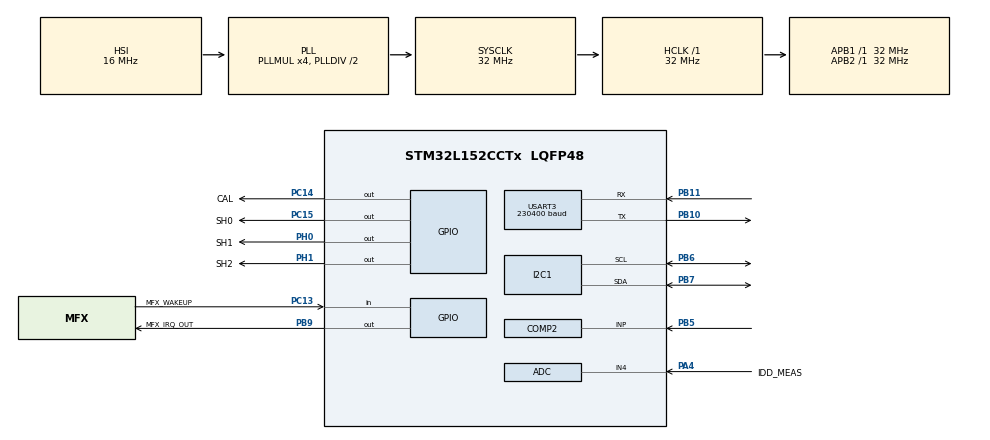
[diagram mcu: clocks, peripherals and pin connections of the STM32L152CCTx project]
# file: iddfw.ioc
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ADC.Channel-0\#ChannelRegularConversion=ADC_CHANNEL_4
ADC.ClockPrescaler=ADC_CLOCK_ASYNC_DIV4
ADC.ContinuousConvMode=DISABLE
ADC.DMAContinuousRequests=DISABLE
ADC.DataAlign=ADC_DATAALIGN_RIGHT
ADC.DiscontinuousConvMode=DISABLE
ADC.EOCSelection=ADC_EOC_SINGLE_CONV
ADC.EnableAnalogWatchDog=false
ADC.ExternalTrigConv=ADC_SOFTWARE_START
ADC.ExternalTrigConvEdge=ADC_EXTERNALTRIGCONVEDGE_NONE
ADC.InjNumberOfConversion=1
ADC.InjectedChannel-4\#ChannelInjectedConversion=ADC_CHANNEL_VREFINT
ADC.InjectedConvMode=AutoInjected
ADC.InjectedOffset-4\#ChannelInjectedConversion=0
ADC.InjectedRank-4\#ChannelInjectedConversion=1
ADC.InjectedSamplingTime-4\#ChannelInjectedConversion=ADC_SAMPLETIME_384CYCLES
ADC.LowPowerAutoPowerOff=ADC_AUTOPOWEROFF_DISABLE
ADC.LowPowerAutoWait=ADC_AUTOWAIT_DISABLE
ADC.NbrOfConversion=1
ADC.NbrOfConversionFlag=1
ADC.Rank-0\#ChannelRegularConversion=1
ADC.Resolution=ADC_RESOLUTION_12B
ADC.SamplingTime-0\#ChannelRegularConversion=ADC_SAMPLETIME_384CYCLES
ADC.ScanConvMode=ADC_SCAN_ENABLE
COMP2.InvertingInput=COMP_INVERTINGINPUT_VREFINT
COMP2.Mode=COMP_MODE_HIGHSPEED
COMP2.TriggerMode=COMP_TRIGGERMODE_IT_RISING_FALLING
Dma.ADC.2.Direction=DMA_PERIPH_TO_MEMORY
Dma.ADC.2.Instance=DMA1_Channel1
Dma.ADC.2.MemDataAlignment=DMA_MDATAALIGN_HALFWORD
Dma.ADC.2.MemInc=DMA_MINC_ENABLE
Dma.ADC.2.Mode=DMA_NORMAL
Dma.ADC.2.PeriphDataAlignment=DMA_PDATAALIGN_HALFWORD
Dma.ADC.2.PeriphInc=DMA_PINC_DISABLE
Dma.ADC.2.Priority=DMA_PRIORITY_LOW
Dma.Request0=USART3_RX
Dma.Request1=USART3_TX
Dma.Request2=ADC
Dma.USART3_RX.0.Direction=DMA_PERIPH_TO_MEMORY
Dma.USART3_RX.0.Instance=DMA1_Channel3
Dma.USART3_RX.0.MemDataAlignment=DMA_MDATAALIGN_BYTE
Dma.USART3_RX.0.MemInc=DMA_MINC_ENABLE
Dma.USART3_RX.0.Mode=DMA_NORMAL
Dma.USART3_RX.0.PeriphDataAlignment=DMA_PDATAALIGN_BYTE
Dma.USART3_RX.0.PeriphInc=DMA_PINC_DISABLE
Dma.USART3_RX.0.Priority=DMA_PRIORITY_LOW
Dma.USART3_TX.1.Direction=DMA_MEMORY_TO_PERIPH
Dma.USART3_TX.1.Instance=DMA1_Channel2
Dma.USART3_TX.1.MemDataAlignment=DMA_MDATAALIGN_BYTE
Dma.USART3_TX.1.MemInc=DMA_MINC_ENABLE
Dma.USART3_TX.1.Mode=DMA_NORMAL
Dma.USART3_TX.1.PeriphDataAlignment=DMA_PDATAALIGN_BYTE
Dma.USART3_TX.1.PeriphInc=DMA_PINC_DISABLE
Dma.USART3_TX.1.Priority=DMA_PRIORITY_LOW
IWDG.Prescaler=IWDG_PRESCALER_128
Mcu.Family=STM32L1
Mcu.Name=STM32L152CCTx
Mcu.Package=LQFP48
NVIC.ADC1_IRQn=true\:0\:0\:false\:false\:true\:true
NVIC.COMP_ACQ_IRQn=true\:0\:0\:false\:false\:true\:true
NVIC.COMP_IRQn=true\:0\:0\:false\:false\:true\:true
NVIC.DMA1_Channel1_IRQn=true\:0\:0\:false\:false\:true\:false
NVIC.DMA1_Channel2_IRQn=true\:0\:0\:false\:false\:true\:true
NVIC.DMA1_Channel3_IRQn=true\:0\:0\:false\:false\:true\:true
NVIC.I2C1_ER_IRQn=true\:0\:0\:false\:false\:true\:true
NVIC.I2C1_EV_IRQn=true\:0\:0\:false\:false\:true\:true
NVIC.PriorityGroup=NVIC_PRIORITYGROUP_4
NVIC.TIM2_IRQn=true\:0\:0\:false\:false\:true\:true
NVIC.TIM5_IRQn=true\:0\:0\:false\:false\:true\:true
NVIC.USART3_IRQn=true\:0\:0\:false\:false\:true\:true
PA13.Mode=Serial_Wire
PA13.Signal=SYS_JTMS-SWDIO
PA14.Mode=Serial_Wire
PA14.Signal=SYS_JTCK-SWCLK
PA4.GPIO_Label=IDD_MEAS
PA4.Mode=IN4
PA4.Signal=ADC_IN4
PB10.Mode=Asynchronous
PB10.Signal=USART3_TX
PB11.Mode=Asynchronous
PB11.Signal=USART3_RX
PB5.Mode=INP
PB5.Signal=COMP2_INP
PB6.Mode=I2C
PB6.Signal=I2C1_SCL
PB7.Mode=I2C
PB7.Signal=I2C1_SDA
PB9.GPIO_Label=MFX_IRQ_OUT
PB9.Signal=GPIO_Output
PC13-WKUP2.GPIO_Label=MFX_WAKEUP
PC13-WKUP2.Signal=GPIO_Input
PC14-OSC32_IN.GPIO_Label=CAL
PC14-OSC32_IN.Signal=GPIO_Output
PC15-OSC32_OUT.GPIO_Label=SH0
PC15-OSC32_OUT.Signal=GPIO_Output
PH0-OSC_IN.GPIO_Label=SH1
PH0-OSC_IN.Signal=GPIO_Output
PH1-OSC_OUT.GPIO_Label=SH2
PH1-OSC_OUT.Signal=GPIO_Output
ProjectManager.HeapSize=0x200
ProjectManager.StackSize=0x400
ProjectManager.TargetToolchain=Makefile
RCC.48MHZClocksFreq_Value=32000000
RCC.AHBFreq_Value=32000000
RCC.APB1Freq_Value=32000000
RCC.APB1TimFreq_Value=32000000
RCC.APB2Freq_Value=32000000
RCC.APB2TimFreq_Value=32000000
RCC.HCLKFreq_Value=32000000
RCC.HSE_VALUE=24000000
RCC.HSI_VALUE=16000000
RCC.LSE_VALUE=32768
RCC.MSIClockRange=RCC_MSIRANGE_6
RCC.MSI_VALUE=4194000
RCC.PLLMUL=RCC_PLL_MUL4
RCC.SYSCLKFreq_VALUE=32000000
RCC.SYSCLKSource=RCC_SYSCLKSOURCE_PLLCLK
RCC.USBOutput=32000000
RCC.VCOOutputFreq_Value=64000000
TIM2.ClockDivision=TIM_CLOCKDIVISION_DIV1
TIM2.CounterMode=TIM_COUNTERMODE_DOWN
TIM2.Period=5000
TIM2.Prescaler=31
TIM5.ClockDivision=TIM_CLOCKDIVISION_DIV1
TIM5.Period=4294967295
USART3.BaudRate=230400
USART3.VirtualMode=VM_ASYNC
VP_ADC_Vref_Input.Mode=IN-Vrefint
VP_COMP2_VS_VREFINT.Mode=VREFINT
VP_IWDG_VS_IWDG.Mode=IWDG_Activate
VP_TIM2_VS_ClockSourceINT.Mode=Internal
VP_TIM5_VS_ClockSourceINT.Mode=Internal
board=iddfw

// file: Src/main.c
/**
  ******************************************************************************
  * @file           : main.c
  * @brief          : Main program body
  ******************************************************************************
  ** This notice applies to any and all portions of this file
  * that are not between comment pairs USER CODE BEGIN and
  * USER CODE END. Other portions of this file, whether
  * inserted by the user or by software development tools
  * are owned by their respective copyright owners.
  *
  * COPYRIGHT(c) 2018 STMicroelectronics
  *
  * Redistribution and use in source and binary forms, with or without modification,
  * are permitted provided that the following conditions are met:
  *   1. Redistributions of source code must retain the above copyright notice,
  *      this list of conditions and the following disclaimer.
  *   2. Redistributions in binary form must reproduce the above copyright notice,
  *      this list of conditions and the following disclaimer in the documentation
  *      and/or other materials provided with the distribution.
  *   3. Neither the name of STMicroelectronics nor the names of its contributors
  *      may be used to endorse or promote products derived from this software
  *      without specific prior written permission.
  *
  * THIS SOFTWARE IS PROVIDED BY THE COPYRIGHT HOLDERS AND CONTRIBUTORS "AS IS"
  * AND ANY EXPRESS OR IMPLIED WARRANTIES, INCLUDING, BUT NOT LIMITED TO, THE
  * IMPLIED WARRANTIES OF MERCHANTABILITY AND FITNESS FOR A PARTICULAR PURPOSE ARE
  * DISCLAIMED. IN NO EVENT SHALL THE COPYRIGHT HOLDER OR CONTRIBUTORS BE LIABLE
  * FOR ANY DIRECT, INDIRECT, INCIDENTAL, SPECIAL, EXEMPLARY, OR CONSEQUENTIAL
  * DAMAGES (INCLUDING, BUT NOT LIMITED TO, PROCUREMENT OF SUBSTITUTE GOODS OR
  * SERVICES; LOSS OF USE, DATA, OR PROFITS; OR BUSINESS INTERRUPTION) HOWEVER
  * CAUSED AND ON ANY THEORY OF LIABILITY, WHETHER IN CONTRACT, STRICT LIABILITY,
  * OR TORT (INCLUDING NEGLIGENCE OR OTHERWISE) ARISING IN ANY WAY OUT OF THE USE
  * OF THIS SOFTWARE, EVEN IF ADVISED OF THE POSSIBILITY OF SUCH DAMAGE.
  *
  ******************************************************************************
  */
#include "main.h"
#include "stm32l1xx_hal.h"
#include "adc.h"
#include "comp.h"
#include "dma.h"
#include "i2c.h"
#include "iwdg.h"
#include "tim.h"
#include "usart.h"
#include "gpio.h"

/* USER CODE BEGIN PV */
/* Private variables ---------------------------------------------------------*/
/* USER CODE END PV */

void SystemClock_Config(void);

/* USER CODE BEGIN PFP */
/* Private function prototypes -----------------------------------------------*/

/* USER CODE END PFP */

/* USER CODE BEGIN 0 */
void MX_Init(void) {
#if 0
/* USER CODE END 0 */

int main(void)
{
  /* USER CODE BEGIN 1 */
#endif
  /* USER CODE END 1 */

  /* MCU Configuration----------------------------------------------------------*/

  /* Reset of all peripherals, Initializes the Flash interface and the Systick. */
  HAL_Init();

  /* Configure the system clock */
  SystemClock_Config();

  /* Initialize all configured peripherals */
  MX_GPIO_Init();
  MX_DMA_Init();
  MX_ADC_Init();
  MX_USART3_UART_Init();
  MX_I2C1_Init();
  MX_COMP2_Init();
  MX_IWDG_Init();
  MX_TIM2_Init();
  MX_TIM5_Init();
  /* USER CODE BEGIN 2 */
  return;
  /* USER CODE END 2 */

  /* Infinite loop */
  while (1)
  {

  }

}

void SystemClock_Config(void)
{

  RCC_OscInitTypeDef RCC_OscInitStruct;
  RCC_ClkInitTypeDef RCC_ClkInitStruct;

    /**Configure the main internal regulator output voltage
    */
  __HAL_PWR_VOLTAGESCALING_CONFIG(PWR_REGULATOR_VOLTAGE_SCALE1);

    /**Initializes the CPU, AHB and APB busses clocks
    */
  RCC_OscInitStruct.OscillatorType = RCC_OSCILLATORTYPE_HSI|RCC_OSCILLATORTYPE_LSI;
  RCC_OscInitStruct.HSIState = RCC_HSI_ON;
  RCC_OscInitStruct.HSICalibrationValue = 16;
  RCC_OscInitStruct.LSIState = RCC_LSI_ON;
  RCC_OscInitStruct.PLL.PLLState = RCC_PLL_ON;
  RCC_OscInitStruct.PLL.PLLSource = RCC_PLLSOURCE_HSI;
  RCC_OscInitStruct.PLL.PLLMUL = RCC_PLL_MUL4;
  RCC_OscInitStruct.PLL.PLLDIV = RCC_PLL_DIV2;
  if (HAL_RCC_OscConfig(&RCC_OscInitStruct) != HAL_OK)
  {
    _Error_Handler(__FILE__, __LINE__);
  }

    /**Initializes the CPU, AHB and APB busses clocks
    */
  RCC_ClkInitStruct.ClockType = RCC_CLOCKTYPE_HCLK|RCC_CLOCKTYPE_SYSCLK
                              |RCC_CLOCKTYPE_PCLK1|RCC_CLOCKTYPE_PCLK2;
  RCC_ClkInitStruct.SYSCLKSource = RCC_SYSCLKSOURCE_PLLCLK;
  RCC_ClkInitStruct.AHBCLKDivider = RCC_SYSCLK_DIV1;
  RCC_ClkInitStruct.APB1CLKDivider = RCC_HCLK_DIV1;
  RCC_ClkInitStruct.APB2CLKDivider = RCC_HCLK_DIV1;

  if (HAL_RCC_ClockConfig(&RCC_ClkInitStruct, FLASH_LATENCY_1) != HAL_OK)
  {
    _Error_Handler(__FILE__, __LINE__);
  }

    /**Configure the Systick interrupt time
    */
  HAL_SYSTICK_Config(HAL_RCC_GetHCLKFreq()/1000);

    /**Configure the Systick
    */
  HAL_SYSTICK_CLKSourceConfig(SYSTICK_CLKSOURCE_HCLK);

  /* SysTick_IRQn interrupt configuration */
  HAL_NVIC_SetPriority(SysTick_IRQn, 0, 0);
}

void _Error_Handler(char *file, int line)
{
  /* USER CODE BEGIN Error_Handler_Debug */
	__BKPT(0);
}
#if 0
  /* User can add his own implementation to report the HAL error return state */
  while(1)
  {
  }
  /* USER CODE END Error_Handler_Debug */
}

#ifdef  USE_FULL_ASSERT
/**
  * @brief  Reports the name of the source file and the source line number
  *         where the assert_param error has occurred.
  * @param  file: pointer to the source file name
  * @param  line: assert_param error line source number
  * @retval None
  */
void assert_failed(uint8_t* file, uint32_t line)
{
  /* USER CODE BEGIN 6 */
  /* User can add his own implementation to report the file name and line number,
     tex: printf("Wrong parameters value: file %s on line %d\r\n", file, line) */
#endif
  /* USER CODE END 6 */
}
#endif /* USE_FULL_ASSERT */

/************************ (C) COPYRIGHT STMicroelectronics *****END OF FILE****/
